AUTOSAR XML (schema 314)
package /ComponentType
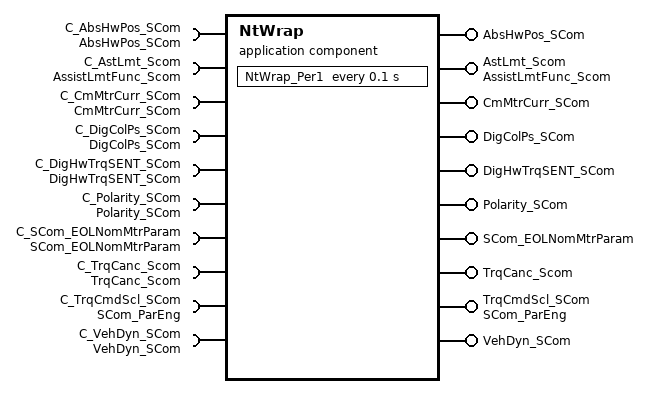
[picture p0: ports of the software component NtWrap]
  application software component type NtWrap
    10 x provide port:
      AbsHwPos_SCom: provided-interface=AbsHwPos_SCom
        provided-com-specs:
          operation=CustClrTrim, queue-length=1
          operation=CustSetTrim, queue-length=1
          operation=NxtClearTrim, queue-length=1
          operation=NxtSetTrim, queue-length=1
      AstLmt_Scom: provided-interface=AssistLmtFunc_Scom
        provided-com-specs:
          operation=GetSteeringAssistDefeat, queue-length=1
          operation=ManualTrqCmd, queue-length=1
          operation=SetSteeringAssistDefeat, queue-length=1
      CmMtrCurr_SCom: provided-interface=CmMtrCurr_SCom
        provided-com-specs:
          operation=CalGain, queue-length=1
          operation=CalOffset, queue-length=1
          operation=MtrCurrOffReadStatus, queue-length=1
          operation=ReadMtrCurrCals, queue-length=1
          operation=SetMtrCurrCals, queue-length=1
      DigColPs_SCom: provided-interface=DigColPs_SCom
        provided-com-specs:
          operation=CustClearTrim, queue-length=1
          operation=CustSetTrim, queue-length=1
          operation=NxtClrTrim, queue-length=1
          operation=NxtSetTrim, queue-length=1
      DigHwTrqSENT_SCom: provided-interface=DigHwTrqSENT_SCom
        provided-com-specs:
          operation=ClrTrqTrim, queue-length=1
          operation=SetTrqTrim, queue-length=1
          operation=TrimData, queue-length=1
          operation=WriteData, queue-length=1
      Polarity_SCom: provided-com-specs=[{operation=ReadPolarity, queue-length=1}, {operation=SetPolarity, queue-length=1}], provided-interface=Polarity_SCom
      SCom_EOLNomMtrParam: provided-com-specs=[{operation=Get, queue-length=1}, {operation=Set, queue-length=1}], provided-interface=SCom_EOLNomMtrParam
      TrqCanc_Scom: provided-interface=TrqCanc_Scom
        provided-com-specs:
          operation=ReadCogTrqCal, queue-length=1
          operation=ReadCogTrqCalComp, queue-length=1
          operation=SetCogTrqCal, queue-length=1
          operation=SetCogTrqCalComp, queue-length=1
      TrqCmdScl_SCom: provided-com-specs=[{operation=Get, queue-length=1}, {operation=Set, queue-length=1}], provided-interface=SCom_ParEng
      VehDyn_SCom: provided-com-specs=[{operation=ForceCenter, queue-length=1}, {operation=ResetCenter, queue-length=1}], provided-interface=VehDyn_SCom
    10 x require port:
      C_AbsHwPos_SCom: required-com-specs=[CustClrTrim, CustSetTrim, NxtClearTrim, NxtSetTrim], required-interface=AbsHwPos_SCom
      C_AstLmt_Scom: required-com-specs=[GetSteeringAssistDefeat, ManualTrqCmd, SetSteeringAssistDefeat], required-interface=AssistLmtFunc_Scom
      C_CmMtrCurr_SCom: required-com-specs=[CalGain, CalOffset, MtrCurrOffReadStatus, ReadMtrCurrCals, SetMtrCurrCals], required-interface=CmMtrCurr_SCom
      C_DigColPs_SCom: required-com-specs=[CustClearTrim, CustSetTrim, NxtClrTrim, NxtSetTrim], required-interface=DigColPs_SCom
      C_DigHwTrqSENT_SCom: required-com-specs=[ClrTrqTrim, SetTrqTrim, TrimData, WriteData], required-interface=DigHwTrqSENT_SCom
      C_Polarity_SCom: required-com-specs=[ReadPolarity, SetPolarity], required-interface=Polarity_SCom
      C_SCom_EOLNomMtrParam: required-com-specs=[Get, Set], required-interface=SCom_EOLNomMtrParam
      C_TrqCanc_Scom: required-com-specs=[ReadCogTrqCal, ReadCogTrqCalComp, SetCogTrqCal, SetCogTrqCalComp], required-interface=TrqCanc_Scom
      C_TrqCmdScl_SCom: required-com-specs=[Get, Set], required-interface=SCom_ParEng
      C_VehDyn_SCom: required-com-specs=[ForceCenter, ResetCenter], required-interface=VehDyn_SCom
  internal behavior NtWrap_InternalBehavior: component=NtWrap
    timing event TMT_NtWrap_Per1: start-on-event=NtWrap_Per1, period=0.1
    20 x operation invoked event:
      OIT_NtWrapC_AbsHwPos_SCom_CustClrTrim_AbsHwPos_SCom_CustClrTrim: start-on-event=NtWrapC_AbsHwPos_SCom_CustClrTrim, operation=AbsHwPos_SCom.CustClrTrim
      OIT_NtWrapC_AbsHwPos_SCom_CustSetTrim_AbsHwPos_SCom_CustSetTrim: start-on-event=NtWrapC_AbsHwPos_SCom_CustSetTrim, operation=AbsHwPos_SCom.CustSetTrim
      OIT_NtWrapC_AbsHwPos_SCom_NxtClearTrim_AbsHwPos_SCom_NxtClearTrim: start-on-event=NtWrapC_AbsHwPos_SCom_NxtClearTrim, operation=AbsHwPos_SCom.NxtClearTrim
      OIT_NtWrapC_AbsHwPos_SCom_NxtSetTrim_AbsHwPos_SCom_NxtSetTrim: start-on-event=NtWrapC_AbsHwPos_SCom_NxtSetTrim, operation=AbsHwPos_SCom.NxtSetTrim
      OIT_NtWrapC_AstLmt_Scom_ManualTrqCmd_AstLmt_Scom_ManualTrqCmd: start-on-event=NtWrapC_AstLmt_Scom_ManualTrqCmd, operation=AstLmt_Scom.ManualTrqCmd
      OIT_NtWrapC_CmMtrCurr_SCom_CalGain_CmMtrCurr_SCom_CalGain: start-on-event=NtWrapC_CmMtrCurr_SCom_CalGain, operation=CmMtrCurr_SCom.CalGain
      OIT_NtWrapC_CmMtrCurr_SCom_CalOffset_CmMtrCurr_SCom_CalOffset: start-on-event=NtWrapC_CmMtrCurr_SCom_CalOffset, operation=CmMtrCurr_SCom.CalOffset
      OIT_NtWrapC_CmMtrCurr_SCom_SetMtrCurrCals_CmMtrCurr_SCom_SetMtrCurrCals: start-on-event=NtWrapC_CmMtrCurr_SCom_SetMtrCurrCals, operation=CmMtrCurr_SCom.SetMtrCurrCals
      OIT_NtWrapC_DigColPs_SCom_CustClrTrim_DigColPs_SCom_CustClearTrim: start-on-event=NtWrapC_DigColPs_SCom_CustClrTrim, operation=DigColPs_SCom.CustClearTrim
      OIT_NtWrapC_DigColPs_SCom_CustSetTrim_DigColPs_SCom_CustSetTrim: start-on-event=NtWrapC_DigColPs_SCom_CustSetTrim, operation=DigColPs_SCom.CustSetTrim
      OIT_NtWrapC_DigColPs_SCom_NxtClrTrim_DigColPs_SCom_NxtClrTrim: start-on-event=NtWrapC_DigColPs_SCom_NxtClrTrim, operation=DigColPs_SCom.NxtClrTrim
      OIT_NtWrapC_DigColPs_SCom_NxtSetTrim_DigColPs_SCom_NxtSetTrim: start-on-event=NtWrapC_DigColPs_SCom_NxtSetTrim, operation=DigColPs_SCom.NxtSetTrim
      OIT_NtWrapC_DigHwTrqSENT_SCom_ClrTrqTrim_DigHwTrqSENT_SCom_ClrTrqTrim: start-on-event=NtWrapC_DigHwTrqSENT_SCom_ClrTrqTrim, operation=DigHwTrqSENT_SCom.ClrTrqTrim
      OIT_NtWrapC_DigHwTrqSENT_SCom_SetTrqTrim_DigHwTrqSENT_SCom_SetTrqTrim: start-on-event=NtWrapC_DigHwTrqSENT_SCom_SetTrqTrim, operation=DigHwTrqSENT_SCom.SetTrqTrim
      OIT_NtWrapC_DigHwTrqSENT_SCom_WriteData_DigHwTrqSENT_SCom_WriteData: start-on-event=NtWrapC_DigHwTrqSENT_SCom_WriteData, operation=DigHwTrqSENT_SCom.WriteData
      OIT_NtWrapC_Polarity_SCom_SetPolarity_Polarity_SCom_SetPolarity: start-on-event=NtWrapC_Polarity_SCom_SetPolarity, operation=Polarity_SCom.SetPolarity
      OIT_NtWrapC_SCom_EOLNomMtrParam_Set_SCom_EOLNomMtrParam_Set: start-on-event=NtWrapC_SCom_EOLNomMtrParam_Set, operation=SCom_EOLNomMtrParam.Set
      OIT_NtWrapC_TrqCanc_Scom_SetCogTrqCal_TrqCanc_Scom_SetCogTrqCal: start-on-event=NtWrapC_TrqCanc_Scom_SetCogTrqCal, operation=TrqCanc_Scom.SetCogTrqCal
      OIT_NtWrapC_TrqCmdScl_SCom_Set_TrqCmdScl_SCom_Set: start-on-event=NtWrapC_TrqCmdScl_SCom_Set, operation=TrqCmdScl_SCom.Set
      OIT_NtWrapC_VehDyn_SCom_ResetCenter_VehDyn_SCom_ResetCenter: start-on-event=NtWrapC_VehDyn_SCom_ResetCenter, operation=VehDyn_SCom.ResetCenter
    port-api-options:
      enable-take-address=false, indirect-api=false, port=AbsHwPos_SCom
      enable-take-address=false, indirect-api=false, port=AstLmt_Scom
      enable-take-address=false, indirect-api=false, port=C_AbsHwPos_SCom
      enable-take-address=false, indirect-api=false, port=C_AstLmt_Scom
      enable-take-address=false, indirect-api=false, port=C_CmMtrCurr_SCom
      enable-take-address=false, indirect-api=false, port=C_DigColPs_SCom
      enable-take-address=false, indirect-api=false, port=C_DigHwTrqSENT_SCom
      enable-take-address=false, indirect-api=false, port=C_Polarity_SCom
      enable-take-address=false, indirect-api=false, port=C_SCom_EOLNomMtrParam
      enable-take-address=false, indirect-api=false, port=C_TrqCanc_Scom
      enable-take-address=false, indirect-api=false, port=C_TrqCmdScl_SCom
      enable-take-address=false, indirect-api=false, port=C_VehDyn_SCom
      enable-take-address=false, indirect-api=false, port=CmMtrCurr_SCom
      enable-take-address=false, indirect-api=false, port=DigColPs_SCom
      enable-take-address=false, indirect-api=false, port=DigHwTrqSENT_SCom
      enable-take-address=false, indirect-api=false, port=Polarity_SCom
      enable-take-address=false, indirect-api=false, port=SCom_EOLNomMtrParam
      enable-take-address=false, indirect-api=false, port=TrqCanc_Scom
      enable-take-address=false, indirect-api=false, port=TrqCmdScl_SCom
      enable-take-address=false, indirect-api=false, port=VehDyn_SCom
    21 x runnable:
      NtWrap_Per1
      NtWrapC_AbsHwPos_SCom_CustClrTrim
        sync call SC_C_AbsHwPos_SCom_CustClrTrim: operation=C_AbsHwPos_SCom.CustClrTrim, timeout=0
      NtWrapC_AbsHwPos_SCom_CustSetTrim
        sync call SC_C_AbsHwPos_SCom_CustSetTrim: operation=C_AbsHwPos_SCom.CustSetTrim, timeout=0
      NtWrapC_AbsHwPos_SCom_NxtClearTrim
        sync call SC_C_AbsHwPos_SCom_NxtClearTrim: operation=C_AbsHwPos_SCom.NxtClearTrim, timeout=0
      NtWrapC_AbsHwPos_SCom_NxtSetTrim
        sync call SC_C_AbsHwPos_SCom_NxtSetTrim: operation=C_AbsHwPos_SCom.NxtSetTrim, timeout=0
      NtWrapC_AstLmt_Scom_ManualTrqCmd
        sync call SC_C_AstLmt_Scom_ManualTrqCmd: operation=C_AstLmt_Scom.ManualTrqCmd, timeout=0
      NtWrapC_CmMtrCurr_SCom_CalGain
        sync call SC_C_CmMtrCurr_SCom_CalGain: operation=C_CmMtrCurr_SCom.CalGain, timeout=0
      NtWrapC_CmMtrCurr_SCom_CalOffset
        sync call SC_C_CmMtrCurr_SCom_CalOffset: operation=C_CmMtrCurr_SCom.CalOffset, timeout=0
      NtWrapC_CmMtrCurr_SCom_SetMtrCurrCals
        sync call SC_C_CmMtrCurr_SCom_SetMtrCurrCals: operation=C_CmMtrCurr_SCom.SetMtrCurrCals, timeout=0
      NtWrapC_DigColPs_SCom_CustClrTrim
        sync call SC_C_DigColPs_SCom_CustClearTrim: operation=C_DigColPs_SCom.CustClearTrim, timeout=0
      NtWrapC_DigColPs_SCom_CustSetTrim
        sync call SC_C_DigColPs_SCom_CustSetTrim: operation=C_DigColPs_SCom.CustSetTrim, timeout=0
      NtWrapC_DigColPs_SCom_NxtClrTrim
        sync call SC_C_DigColPs_SCom_NxtClrTrim: operation=C_DigColPs_SCom.NxtClrTrim, timeout=0
      NtWrapC_DigColPs_SCom_NxtSetTrim
        sync call SC_C_DigColPs_SCom_NxtSetTrim: operation=C_DigColPs_SCom.NxtSetTrim, timeout=0
      NtWrapC_DigHwTrqSENT_SCom_ClrTrqTrim
        sync call SC_C_DigHwTrqSENT_SCom_ClrTrqTrim: operation=C_DigHwTrqSENT_SCom.ClrTrqTrim, timeout=0
      NtWrapC_DigHwTrqSENT_SCom_SetTrqTrim
        sync call SC_C_DigHwTrqSENT_SCom_SetTrqTrim: operation=C_DigHwTrqSENT_SCom.SetTrqTrim, timeout=0
      NtWrapC_DigHwTrqSENT_SCom_WriteData
        sync call SC_C_DigHwTrqSENT_SCom_WriteData: operation=C_DigHwTrqSENT_SCom.WriteData, timeout=0
      NtWrapC_Polarity_SCom_SetPolarity
        sync call SC_C_Polarity_SCom_SetPolarity: operation=C_Polarity_SCom.SetPolarity, timeout=0
      NtWrapC_SCom_EOLNomMtrParam_Set
        sync call SC_C_SCom_EOLNomMtrParam_Set: operation=C_SCom_EOLNomMtrParam.Set, timeout=0
      NtWrapC_TrqCanc_Scom_SetCogTrqCal
        sync call SC_C_TrqCanc_Scom_SetCogTrqCal: operation=C_TrqCanc_Scom.SetCogTrqCal, timeout=0
      NtWrapC_TrqCmdScl_SCom_Set
        sync call SC_C_TrqCmdScl_SCom_Set: operation=C_TrqCmdScl_SCom.Set, timeout=0
      NtWrapC_VehDyn_SCom_ResetCenter
        sync call SC_C_VehDyn_SCom_ResetCenter: operation=C_VehDyn_SCom.ResetCenter, timeout=0
  swc implementation NtWrap_Implementation: behavior=NtWrap_InternalBehavior
    code-descriptors:
      code Code: type=SRC
